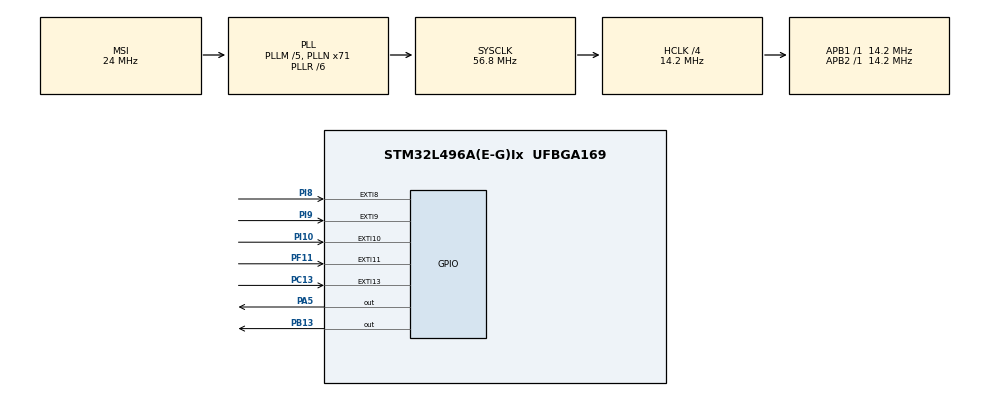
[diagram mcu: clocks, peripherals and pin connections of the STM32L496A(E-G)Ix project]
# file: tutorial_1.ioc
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Mcu.Family=STM32L4
Mcu.Name=STM32L496A(E-G)Ix
Mcu.Package=UFBGA169
NVIC.EXTI15_10_IRQn=true\:0\:0\:false\:false\:true\:true\:true\:true
NVIC.EXTI9_5_IRQn=true\:0\:0\:false\:false\:true\:true\:true\:true
NVIC.PriorityGroup=NVIC_PRIORITYGROUP_4
PA5.Signal=GPIO_Output
PB13.Signal=GPIO_Output
PC13.GPIO_PuPd=GPIO_PULLDOWN
PC13.Signal=GPXTI13
PF11.GPIO_PuPd=GPIO_PULLDOWN
PF11.Signal=GPXTI11
PI10.GPIO_PuPd=GPIO_PULLDOWN
PI10.Signal=GPXTI10
PI8.GPIO_PuPd=GPIO_PULLDOWN
PI8.Signal=GPXTI8
PI9.GPIO_PuPd=GPIO_PULLDOWN
PI9.Signal=GPXTI9
ProjectManager.HeapSize=0x200
ProjectManager.StackSize=0x400
ProjectManager.TargetToolchain=STM32CubeIDE
RCC.ADCFreq_Value=48000000
RCC.AHBCLKDivider=RCC_SYSCLK_DIV4
RCC.AHBFreq_Value=14200000
RCC.APB1Freq_Value=14200000
RCC.APB1TimFreq_Value=14200000
RCC.APB2Freq_Value=14200000
RCC.APB2TimFreq_Value=14200000
RCC.CortexFreq_Value=14200000
RCC.HCLKFreq_Value=14200000
RCC.HSE_VALUE=8000000
RCC.HSI48_VALUE=48000000
RCC.HSI_VALUE=16000000
RCC.LSE_VALUE=32768
RCC.MSIClockRange=RCC_MSIRANGE_9
RCC.MSI_VALUE=24000000
RCC.PLLM=5
RCC.PLLN=71
RCC.PLLR=RCC_PLLR_DIV6
RCC.PLLSAI1N=20
RCC.SYSCLKFreq_VALUE=56800000
RCC.SYSCLKSource=RCC_SYSCLKSOURCE_PLLCLK
RCC.USBFreq_Value=48000000
RCC.VCOOutputFreq_Value=340800000
board=STM32L496G-DISCO

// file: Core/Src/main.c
/* USER CODE BEGIN Header */
/**
  ******************************************************************************
  * @file           : main.c
  * @brief          : Main program body
  ******************************************************************************
  * @attention
  *
  * Copyright (c) 2022 STMicroelectronics.
  * All rights reserved.
  *
  * This software is licensed under terms that can be found in the LICENSE file
  * in the root directory of this software component.
  * If no LICENSE file comes with this software, it is provided AS-IS.
  *
  ******************************************************************************
  */
/* USER CODE END Header */
#include "main.h"

void SystemClock_Config(void);
static void MX_GPIO_Init(void);

int main(void)
{

  /* MCU Configuration--------------------------------------------------------*/

  /* Reset of all peripherals, Initializes the Flash interface and the Systick. */
  HAL_Init();

  /* Configure the system clock */
  SystemClock_Config();

  /* Initialize all configured peripherals */
  MX_GPIO_Init();

  /* Infinite loop */
  while (1)
  {
  }
}

void SystemClock_Config(void)
{
  RCC_OscInitTypeDef RCC_OscInitStruct = {0};
  RCC_ClkInitTypeDef RCC_ClkInitStruct = {0};

  /** Configure the main internal regulator output voltage
  */
  if (HAL_PWREx_ControlVoltageScaling(PWR_REGULATOR_VOLTAGE_SCALE1) != HAL_OK)
  {
    Error_Handler();
  }

  /** Initializes the RCC Oscillators according to the specified parameters
  * in the RCC_OscInitTypeDef structure.
  */
  RCC_OscInitStruct.OscillatorType = RCC_OSCILLATORTYPE_MSI;
  RCC_OscInitStruct.MSIState = RCC_MSI_ON;
  RCC_OscInitStruct.MSICalibrationValue = 0;
  RCC_OscInitStruct.MSIClockRange = RCC_MSIRANGE_9;
  RCC_OscInitStruct.PLL.PLLState = RCC_PLL_ON;
  RCC_OscInitStruct.PLL.PLLSource = RCC_PLLSOURCE_MSI;
  RCC_OscInitStruct.PLL.PLLM = 5;
  RCC_OscInitStruct.PLL.PLLN = 71;
  RCC_OscInitStruct.PLL.PLLP = RCC_PLLP_DIV2;
  RCC_OscInitStruct.PLL.PLLQ = RCC_PLLQ_DIV2;
  RCC_OscInitStruct.PLL.PLLR = RCC_PLLR_DIV6;
  if (HAL_RCC_OscConfig(&RCC_OscInitStruct) != HAL_OK)
  {
    Error_Handler();
  }

  /** Initializes the CPU, AHB and APB buses clocks
  */
  RCC_ClkInitStruct.ClockType = RCC_CLOCKTYPE_HCLK|RCC_CLOCKTYPE_SYSCLK
                              |RCC_CLOCKTYPE_PCLK1|RCC_CLOCKTYPE_PCLK2;
  RCC_ClkInitStruct.SYSCLKSource = RCC_SYSCLKSOURCE_PLLCLK;
  RCC_ClkInitStruct.AHBCLKDivider = RCC_SYSCLK_DIV4;
  RCC_ClkInitStruct.APB1CLKDivider = RCC_HCLK_DIV1;
  RCC_ClkInitStruct.APB2CLKDivider = RCC_HCLK_DIV1;

  if (HAL_RCC_ClockConfig(&RCC_ClkInitStruct, FLASH_LATENCY_0) != HAL_OK)
  {
    Error_Handler();
  }
}

static void MX_GPIO_Init(void)
{
  GPIO_InitTypeDef GPIO_InitStruct = {0};

  /* GPIO Ports Clock Enable */
  __HAL_RCC_GPIOI_CLK_ENABLE();
  __HAL_RCC_GPIOC_CLK_ENABLE();
  __HAL_RCC_GPIOA_CLK_ENABLE();
  __HAL_RCC_GPIOF_CLK_ENABLE();
  __HAL_RCC_GPIOB_CLK_ENABLE();

  /*Configure GPIO pin Output Level */
  HAL_GPIO_WritePin(GPIOA, GPIO_PIN_5, GPIO_PIN_RESET);

  /*Configure GPIO pin Output Level */
  HAL_GPIO_WritePin(GPIOB, GPIO_PIN_13, GPIO_PIN_RESET);

  /*Configure GPIO pins : PI10 PI9 PI8 */
  GPIO_InitStruct.Pin = GPIO_PIN_10|GPIO_PIN_9|GPIO_PIN_8;
  GPIO_InitStruct.Mode = GPIO_MODE_IT_RISING;
  GPIO_InitStruct.Pull = GPIO_PULLDOWN;
  HAL_GPIO_Init(GPIOI, &GPIO_InitStruct);

  /*Configure GPIO pin : PC13 */
  GPIO_InitStruct.Pin = GPIO_PIN_13;
  GPIO_InitStruct.Mode = GPIO_MODE_IT_RISING;
  GPIO_InitStruct.Pull = GPIO_PULLDOWN;
  HAL_GPIO_Init(GPIOC, &GPIO_InitStruct);

  /*Configure GPIO pin : PA5 */
  GPIO_InitStruct.Pin = GPIO_PIN_5;
  GPIO_InitStruct.Mode = GPIO_MODE_OUTPUT_PP;
  GPIO_InitStruct.Pull = GPIO_NOPULL;
  GPIO_InitStruct.Speed = GPIO_SPEED_FREQ_LOW;
  HAL_GPIO_Init(GPIOA, &GPIO_InitStruct);

  /*Configure GPIO pin : PF11 */
  GPIO_InitStruct.Pin = GPIO_PIN_11;
  GPIO_InitStruct.Mode = GPIO_MODE_IT_RISING;
  GPIO_InitStruct.Pull = GPIO_PULLDOWN;
  HAL_GPIO_Init(GPIOF, &GPIO_InitStruct);

  /*Configure GPIO pin : PB13 */
  GPIO_InitStruct.Pin = GPIO_PIN_13;
  GPIO_InitStruct.Mode = GPIO_MODE_OUTPUT_PP;
  GPIO_InitStruct.Pull = GPIO_NOPULL;
  GPIO_InitStruct.Speed = GPIO_SPEED_FREQ_LOW;
  HAL_GPIO_Init(GPIOB, &GPIO_InitStruct);

  /* EXTI interrupt init*/
  HAL_NVIC_SetPriority(EXTI9_5_IRQn, 0, 0);
  HAL_NVIC_EnableIRQ(EXTI9_5_IRQn);

  HAL_NVIC_SetPriority(EXTI15_10_IRQn, 0, 0);
  HAL_NVIC_EnableIRQ(EXTI15_10_IRQn);

}

/* USER CODE BEGIN 4 */
void HAL_GPIO_EXTI_Callback(uint16_t GPIO_Pin)
{
	if(GPIO_Pin == GPIO_PIN_8) //Up -> LD2 off LD3 on
	{
		HAL_GPIO_WritePin(GPIOA, GPIO_PIN_5, GPIO_PIN_SET);
		HAL_GPIO_WritePin(GPIOB, GPIO_PIN_13, GPIO_PIN_SET);
	}

	if(GPIO_Pin == GPIO_PIN_10) //Down -> LD2 on LD3 off
	{
		HAL_GPIO_WritePin(GPIOA, GPIO_PIN_5, GPIO_PIN_RESET);
		HAL_GPIO_WritePin(GPIOB, GPIO_PIN_13, GPIO_PIN_RESET);
	}

	if(GPIO_Pin == GPIO_PIN_9) //Left -> LD2 LD3 on
	{
		HAL_GPIO_WritePin(GPIOA, GPIO_PIN_5, GPIO_PIN_SET);
		HAL_GPIO_WritePin(GPIOB, GPIO_PIN_13, GPIO_PIN_RESET);
	}

	if(GPIO_Pin == GPIO_PIN_11) //Right -> LD2 LD3 off
	{
		HAL_GPIO_WritePin(GPIOA, GPIO_PIN_5, GPIO_PIN_RESET);
		HAL_GPIO_WritePin(GPIOB, GPIO_PIN_13, GPIO_PIN_SET);
	}
}

/* USER CODE END 4 */

void Error_Handler(void)
{
  __disable_irq();
  while (1)
  {
  }
}
